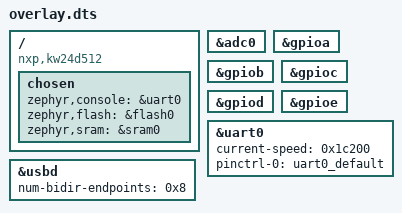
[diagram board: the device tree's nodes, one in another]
/ {
	compatible = "nxp,kw24d512", "nxp,kw2xd", "nxp,usb-kw24d512";
	chosen {
		zephyr,console = &uart0;
		zephyr,flash = &flash0;
		zephyr,sram = &sram0;
	};
};
&adc0{
	status = "okay";
};
&gpioa{
	status = "okay";
};
&gpiob{
	status = "okay";
};
&gpioc{
	status = "okay";
};
&gpiod{
	status = "okay";
};
&gpioe{
	status = "okay";
};
&uart0{
	status = "okay";
	current-speed = < 0x1c200 >;
	pinctrl-0 = < &uart0_default >;
	pinctrl-names = "default";
};
&usbd{
	num-bidir-endpoints = < 0x8 >;
	status = "okay";
};
